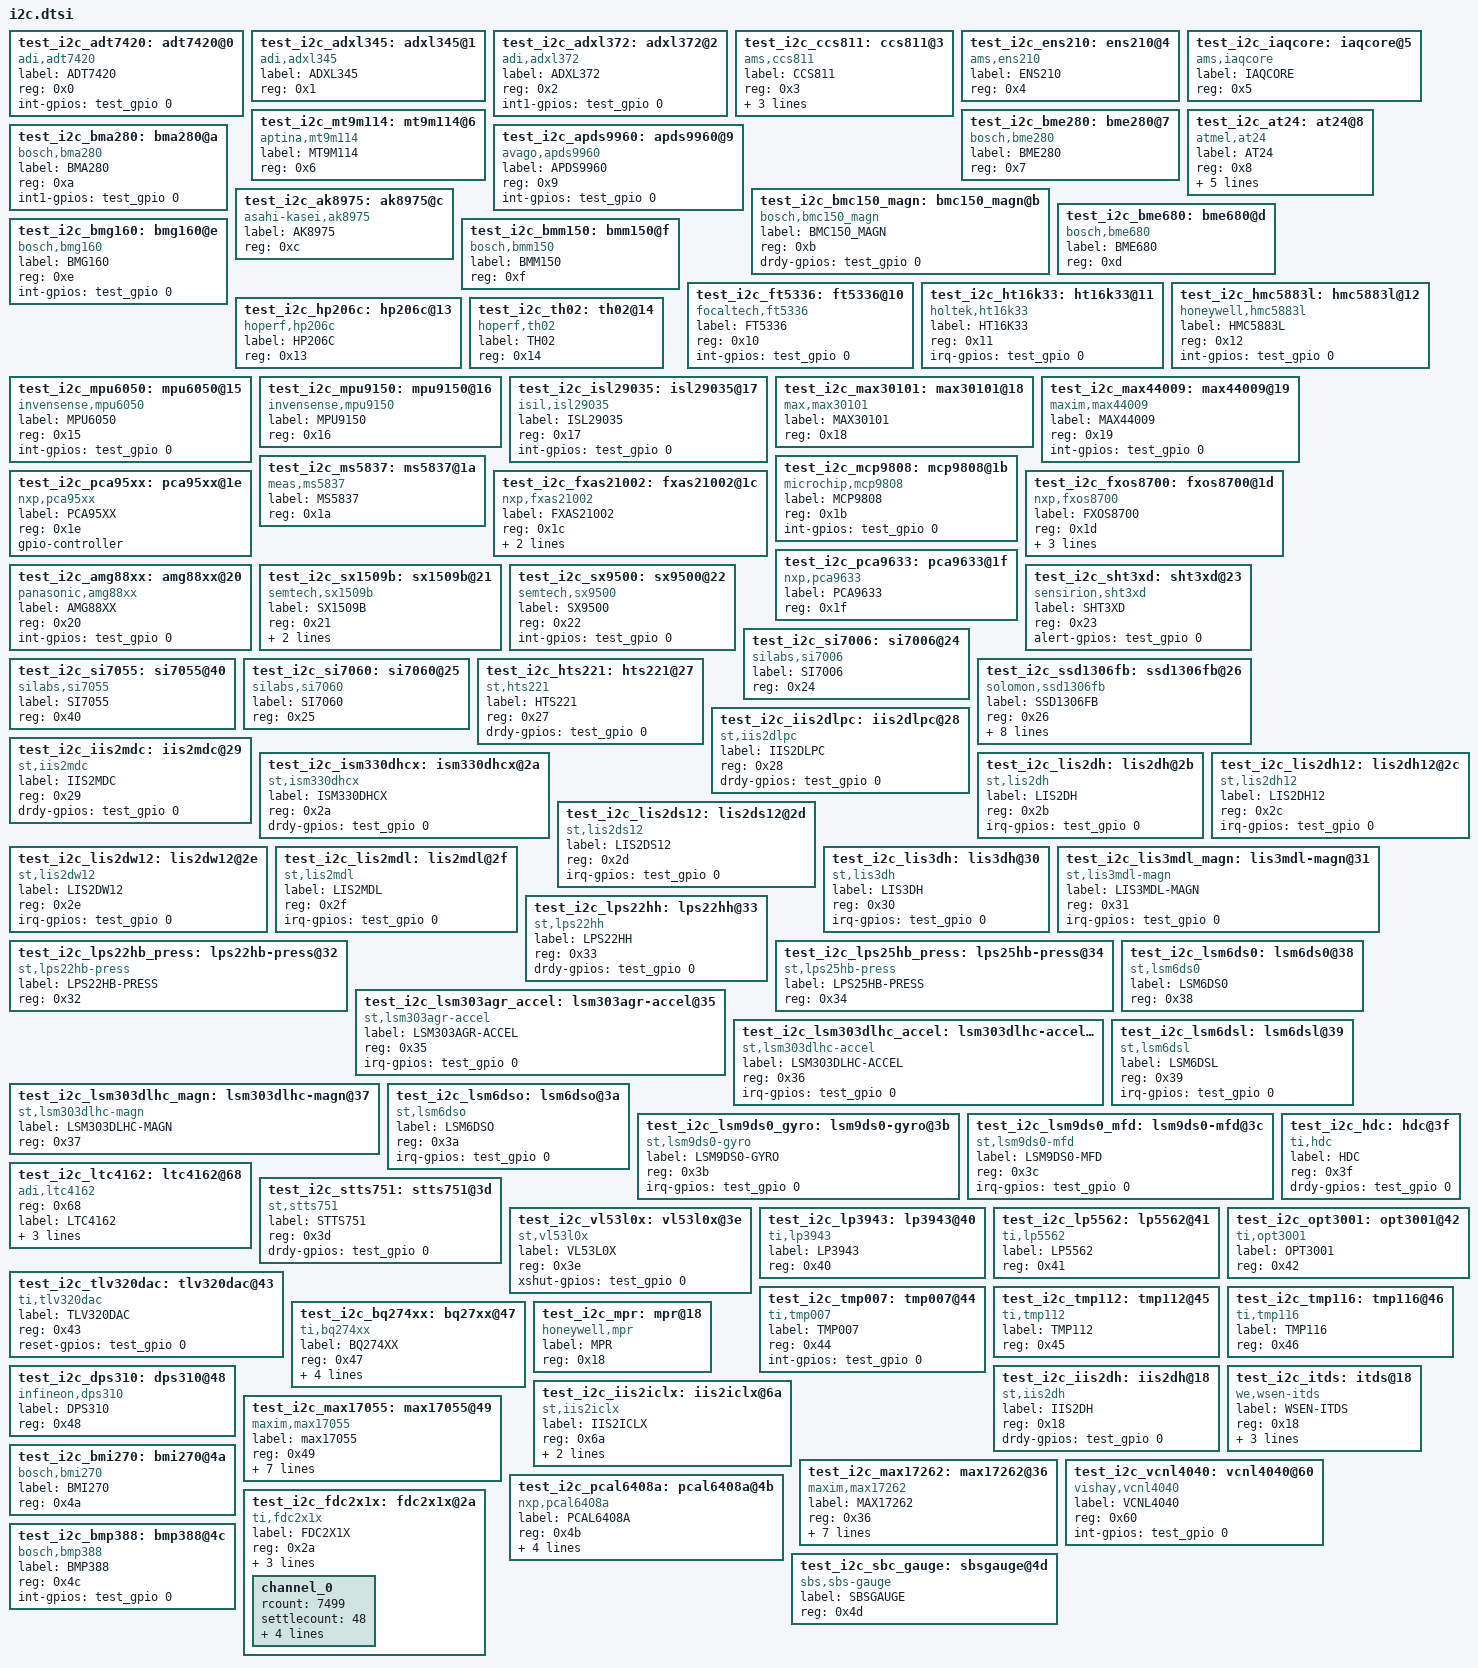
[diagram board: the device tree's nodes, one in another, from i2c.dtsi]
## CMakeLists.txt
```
# SPDX-License-Identifier: Apache-2.0

cmake_minimum_required(VERSION 3.13.1)
find_package(Zephyr REQUIRED HINTS $ENV{ZEPHYR_BASE})
project(build_all)

FILE(GLOB app_sources src/*.c)
target_sources(app PRIVATE ${app_sources})
```

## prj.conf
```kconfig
CONFIG_TEST=y
CONFIG_TEST_USERSPACE=y
CONFIG_SYS_TIMEOUT_LEGACY_API=y
CONFIG_SYS_TIMEOUT_LEGACY_API=y
CONFIG_SYS_TIMEOUT_LEGACY_API=y
CONFIG_SYS_TIMEOUT_LEGACY_API=y
CONFIG_SYS_TIMEOUT_LEGACY_API=y
```

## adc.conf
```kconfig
CONFIG_ADC=y
CONFIG_SPI=y
CONFIG_ADC_MCP320X=y
CONFIG_TEST_USERSPACE=y
```

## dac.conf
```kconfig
CONFIG_DAC=y
CONFIG_SPI=y
CONFIG_DAC_DACX0508=y
CONFIG_TEST_USERSPACE=y
```

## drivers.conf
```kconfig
CONFIG_TEST=y
CONFIG_ADC=y
CONFIG_CAN=y
CONFIG_COUNTER=y
CONFIG_DMA=y
CONFIG_GPIO=y
CONFIG_I2C=y
CONFIG_PINMUX=y
CONFIG_PWM=y
CONFIG_SERIAL=y
CONFIG_SPI=y
CONFIG_WATCHDOG=y
CONFIG_TEST_USERSPACE=y
```

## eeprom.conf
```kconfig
CONFIG_EEPROM=y
CONFIG_GPIO=y
CONFIG_I2C=y
CONFIG_SPI=y
CONFIG_EEPROM_AT24=y
CONFIG_EEPROM_AT25=y
CONFIG_TEST_USERSPACE=y
```

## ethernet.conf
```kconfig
CONFIG_TEST=y
CONFIG_NET_TEST=y
CONFIG_NETWORKING=y
CONFIG_NET_L2_ETHERNET=y
CONFIG_ENTROPY_GENERATOR=y
CONFIG_TEST_RANDOM_GENERATOR=y
CONFIG_TEST_USERSPACE=y

# No board will enable the generic SPI hosted enc28j60 driver by
# default, force it on:
CONFIG_SPI=y
CONFIG_ETH_ENC28J60=y
CONFIG_ETH_ENC28J60_0=y
CONFIG_SYS_TIMEOUT_LEGACY_API=y
CONFIG_SYS_TIMEOUT_LEGACY_API=y
CONFIG_SYS_TIMEOUT_LEGACY_API=y
CONFIG_SYS_TIMEOUT_LEGACY_API=y
CONFIG_SYS_TIMEOUT_LEGACY_API=y
```

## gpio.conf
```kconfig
CONFIG_TEST=y
CONFIG_GPIO=y
CONFIG_TEST_USERSPACE=y
CONFIG_I2C=y
CONFIG_GPIO_SX1509B=y
CONFIG_SPI=y
CONFIG_GPIO_MCP23X17=y
```

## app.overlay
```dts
/*
 * Copyright (c) 2020, Linaro Ltd.
 *
 * SPDX-License-Identifier: Apache-2.0
 *
 * Application overlay for testing driver builds
 *
 * Names in this file should be chosen in a way that won't conflict
 * with real-world devicetree nodes, to allow these tests to run on
 * (and be extended to test) real hardware.
 */

/ {
	test {
		#address-cells = <1>;
		#size-cells = <1>;

		test_gpio: gpio@deadbeef {
			compatible = "vnd,gpio";
			gpio-controller;
			reg = <0xdeadbeef 0x1000>;
			#gpio-cells = <0x2>;
			label = "TEST_GPIO_1";
			status = "okay";

			#include "gpio.dtsi"
		};

		test_i2c: i2c@11112222 {
			#address-cells = <1>;
			#size-cells = <0>;
			compatible = "vnd,i2c";
			reg = <0x11112222 0x1000>;
			label = "TEST_I2C_CTLR";
			status = "okay";
			clock-frequency = <100000>;

			#include "i2c.dtsi"
		};

		test_spi: spi@33334444 {
			#address-cells = <1>;
			#size-cells = <0>;
			compatible = "vnd,spi";
			reg = <0x33334444 0x1000>;
			label = "TEST_SPI_CTLR";
			status = "okay";
			clock-frequency = <2000000>;

			/* one entry for every devices at spi.dtsi */
			cs-gpios = <&test_gpio 0 0>,	/* 0x00 */
				   <&test_gpio 0 0>,
				   <&test_gpio 0 0>,
				   <&test_gpio 0 0>,
				   <&test_gpio 0 0>,
				   <&test_gpio 0 0>,
				   <&test_gpio 0 0>,
				   <&test_gpio 0 0>,
				   <&test_gpio 0 0>,
				   <&test_gpio 0 0>,
				   <&test_gpio 0 0>,
				   <&test_gpio 0 0>,
				   <&test_gpio 0 0>,
				   <&test_gpio 0 0>,
				   <&test_gpio 0 0>,
				   <&test_gpio 0 0>,
				   <&test_gpio 0 0>,	/* 0x10 */
				   <&test_gpio 0 0>,
				   <&test_gpio 0 0>,
				   <&test_gpio 0 0>,
				   <&test_gpio 0 0>,
				   <&test_gpio 0 0>,
				   <&test_gpio 0 0>,
				   <&test_gpio 0 0>,
				   <&test_gpio 0 0>,
				   <&test_gpio 0 0>,
				   <&test_gpio 0 0>,
				   <&test_gpio 0 0>,
				   <&test_gpio 0 0>,
				   <&test_gpio 0 0>,
				   <&test_gpio 0 0>,
				   <&test_gpio 0 0>,
				   <&test_gpio 0 0>,	/* 0x20 */
				   <&test_gpio 0 0>,
				   <&test_gpio 0 0>,
				   <&test_gpio 0 0>,
				   <&test_gpio 0 0>,
				   <&test_gpio 0 0>,
				   <&test_gpio 0 0>,
				   <&test_gpio 0 0>,
				   <&test_gpio 0 0>,
				   <&test_gpio 0 0>,
				   <&test_gpio 0 0>,
				   <&test_gpio 0 0>,
				   <&test_gpio 0 0>,
				   <&test_gpio 0 0>,
				   <&test_gpio 0 0>,
				   <&test_gpio 0 0>,
				   <&test_gpio 0 0>,	/* 0x30 */
				   <&test_gpio 0 0>,
				   <&test_gpio 0 0>,
				   <&test_gpio 0 0>,
				   <&test_gpio 0 0>,
				   <&test_gpio 0 0>,
				   <&test_gpio 0 0>,
				   <&test_gpio 0 0>,
				   <&test_gpio 0 0>,
				   <&test_gpio 0 0>,
				   <&test_gpio 0 0>,
				   <&test_gpio 0 0>,
				   <&test_gpio 0 0>,
				   <&test_gpio 0 0>,
				   <&test_gpio 0 0>,
				   <&test_gpio 0 0>,
				   <&test_gpio 0 0>;	/* 0x40 */

			#include "spi.dtsi"
		};

		test_uart: uart@55556666 {
			compatible = "vnd,serial";
			reg = <0x55556666 0x1000>;
			label = "TEST_UART_CTLR";
			status = "okay";

			#include "uart.dtsi"
		};

		#include "led.dtsi"

		dht22 {
			compatible = "aosong,dht";
			status = "okay";
			label = "DHT22";
			dio-gpios = <&test_gpio 0 0>;
			/* dht22; */
		};
	};
};

/* Put device specific modifications to properties or disabling of devices
 * here to keep the bus specific dtsi files (i2c.dtsi, spi.dtsi, etc..)
 * pristine
 */

/* setup valid params for the device */
&test_i2c_at24 {
	reg = <0x8>;
	size = <32768>;
	pagesize = <64>;
	address-width = <16>;
	timeout = <5>;
};

/* disable device to conflict with i2c version */
&test_i2c_iis2dlpc {
	status = "disabled";
};

/* disable device to conflict with i2c version */
&test_i2c_ism330dhcx {
	status = "disabled";
};

/* disable device to conflict with i2c version */
&test_i2c_lis2dh {
	status = "disabled";
};

/* disable device to conflict with i2c version */
&test_i2c_lis2ds12 {
	status = "disabled";
};

/* disable device to conflict with i2c version */
&test_i2c_lis2dw12 {
	status = "disabled";
};

/* disable device to conflict with i2c version */
&test_i2c_lis2mdl {
	status = "disabled";
};

/* disable device to conflict with i2c version */
&test_i2c_lps22hh {
	status = "disabled";
};

/* disable device to conflict with i2c version */
&test_i2c_lsm6dsl {
	status = "disabled";
};

/* disable device to conflict with i2c version */
&test_i2c_lsm6dso {
	status = "disabled";
};

/* setup valid params for the device */
&test_spi_at25 {
	size = <32768>;
	pagesize = <64>;
	address-width = <16>;
	timeout = <5>;
};

/* disable device to conflict with i2c version */
&test_spi_bme280 {
	status = "disabled";
};

/* setup valid params for the device */
&test_spi_enc28j60 {
	local-mac-address = [00 00 00 00 00 00];
};

/* disable device to conflict with i2c version */
&test_spi_iis2iclx {
	status = "disabled";
};

/* disable device to conflict with i2c version */
&test_spi_iis2mdc {
	status = "disabled";
};

/* setup valid params for the device */
&test_spi_iis3dhhc {
	irq-gpios = <&test_gpio 0 0>, <&test_gpio 0 0>;
};

/* disable device to conflict with i2c version */
&test_spi_iis2dh {
	status = "disabled";
};
```

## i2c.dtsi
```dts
/*
 * Copyright (c) 2020, Linaro Ltd.
 *
 * SPDX-License-Identifier: Apache-2.0
 *
 * Application overlay for i2c devices
 */

test_i2c_adt7420: adt7420@0 {
	compatible = "adi,adt7420";
	label = "ADT7420";
	reg = <0x0>;
	int-gpios = <&test_gpio 0 0>;
};

test_i2c_adxl345: adxl345@1 {
	compatible = "adi,adxl345";
	label = "ADXL345";
	reg = <0x1>;
};

test_i2c_adxl372: adxl372@2 {
	compatible = "adi,adxl372";
	label = "ADXL372";
	reg = <0x2>;
	int1-gpios = <&test_gpio 0 0>;
};

test_i2c_ccs811: ccs811@3 {
	compatible = "ams,ccs811";
	label = "CCS811";
	reg = <0x3>;
	wake-gpios = <&test_gpio 0 0>;
	reset-gpios = <&test_gpio 0 0>;
	irq-gpios = <&test_gpio 0 0>;
};

test_i2c_ens210: ens210@4 {
	compatible = "ams,ens210";
	label = "ENS210";
	reg = <0x4>;
};

test_i2c_iaqcore: iaqcore@5 {
	compatible = "ams,iaqcore";
	label = "IAQCORE";
	reg = <0x5>;
};

test_i2c_mt9m114: mt9m114@6 {
	compatible = "aptina,mt9m114";
	label = "MT9M114";
	reg = <0x6>;
};

test_i2c_bme280: bme280@7 {
	compatible = "bosch,bme280";
	label = "BME280";
	reg = <0x7>;
};

test_i2c_at24: at24@8 {
	compatible = "atmel,at24";
	label = "AT24";
	reg = <0x8>;
	size = <0>;
	pagesize = <0>;
	address-width = <0>;
	timeout = <0>;
	wp-gpios = <&test_gpio 0 0>;
	/* read-only; */
};

test_i2c_apds9960: apds9960@9 {
	compatible = "avago,apds9960";
	label = "APDS9960";
	reg = <0x9>;
	int-gpios = <&test_gpio 0 0>;
};

test_i2c_bma280: bma280@a {
	compatible = "bosch,bma280";
	label = "BMA280";
	reg = <0xa>;
	int1-gpios = <&test_gpio 0 0>;
	/* is-bmc150; */
};

test_i2c_bmc150_magn: bmc150_magn@b {
	compatible = "bosch,bmc150_magn";
	label = "BMC150_MAGN";
	reg = <0xb>;
	drdy-gpios = <&test_gpio 0 0>;
};

test_i2c_ak8975: ak8975@c {
	compatible = "asahi-kasei,ak8975";
	label = "AK8975";
	reg = <0xc>;
};

test_i2c_bme680: bme680@d {
	compatible = "bosch,bme680";
	label = "BME680";
	reg = <0xd>;
};

test_i2c_bmg160: bmg160@e {
	compatible = "bosch,bmg160";
	label = "BMG160";
	reg = <0xe>;
	int-gpios = <&test_gpio 0 0>;
};

test_i2c_bmm150: bmm150@f {
	compatible = "bosch,bmm150";
	label = "BMM150";
	reg = <0xf>;
};

test_i2c_ft5336: ft5336@10 {
	compatible = "focaltech,ft5336";
	label = "FT5336";
	reg = <0x10>;
	int-gpios = <&test_gpio 0 0>;
};

test_i2c_ht16k33: ht16k33@11 {
	compatible = "holtek,ht16k33";
	label = "HT16K33";
	reg = <0x11>;
	#address-cells = <1>;
	#size-cells = <0>;
	irq-gpios = <&test_gpio 0 0>;
};

test_i2c_hmc5883l: hmc5883l@12 {
	compatible = "honeywell,hmc5883l";
	label = "HMC5883L";
	reg = <0x12>;
	int-gpios = <&test_gpio 0 0>;
};

test_i2c_hp206c: hp206c@13 {
	compatible = "hoperf,hp206c";
	label = "HP206C";
	reg = <0x13>;
};

test_i2c_th02: th02@14 {
	compatible = "hoperf,th02";
	label = "TH02";
	reg = <0x14>;
};

test_i2c_mpu6050: mpu6050@15 {
	compatible = "invensense,mpu6050";
	label = "MPU6050";
	reg = <0x15>;
	int-gpios = <&test_gpio 0 0>;
};

test_i2c_mpu9150: mpu9150@16 {
	compatible = "invensense,mpu9150";
	label = "MPU9150";
	reg = <0x16>;
};

test_i2c_isl29035: isl29035@17 {
	compatible = "isil,isl29035";
	label = "ISL29035";
	reg = <0x17>;
	int-gpios = <&test_gpio 0 0>;
};

test_i2c_max30101: max30101@18 {
	compatible = "max,max30101";
	label = "MAX30101";
	reg = <0x18>;
};

test_i2c_max44009: max44009@19 {
	compatible = "maxim,max44009";
	label = "MAX44009";
	reg = <0x19>;
	int-gpios = <&test_gpio 0 0>;
};

test_i2c_ms5837: ms5837@1a {
	compatible = "meas,ms5837";
	label = "MS5837";
	reg = <0x1a>;
};

test_i2c_mcp9808: mcp9808@1b {
	compatible = "microchip,mcp9808";
	label = "MCP9808";
	reg = <0x1b>;
	int-gpios = <&test_gpio 0 0>;
};

test_i2c_fxas21002: fxas21002@1c {
	compatible = "nxp,fxas21002";
	label = "FXAS21002";
	reg = <0x1c>;
	int1-gpios = <&test_gpio 0 0>;
	int2-gpios = <&test_gpio 0 0>;
};

test_i2c_fxos8700: fxos8700@1d {
	compatible = "nxp,fxos8700";
	label = "FXOS8700";
	reg = <0x1d>;
	reset-gpios = <&test_gpio 0 0>;
	int1-gpios = <&test_gpio 0 0>;
	int2-gpios = <&test_gpio 0 0>;
};

test_i2c_pca95xx: pca95xx@1e {
	compatible = "nxp,pca95xx";
	label = "PCA95XX";
	reg = <0x1e>;
	/* has-pud; */
	#gpio-cells = <2>;
	gpio-controller;
};

test_i2c_pca9633: pca9633@1f {
	compatible = "nxp,pca9633";
	label = "PCA9633";
	reg = <0x1f>;
};

test_i2c_amg88xx: amg88xx@20 {
	compatible = "panasonic,amg88xx";
	label = "AMG88XX";
	reg = <0x20>;
	int-gpios = <&test_gpio 0 0>;
};

test_i2c_sx1509b: sx1509b@21 {
	compatible = "semtech,sx1509b";
	label = "SX1509B";
	reg = <0x21>;
	#gpio-cells = <2>;
	ngpios = <16>;
	gpio-controller;
};

test_i2c_sx9500: sx9500@22 {
	compatible = "semtech,sx9500";
	label = "SX9500";
	reg = <0x22>;
	int-gpios = <&test_gpio 0 0>;
};

test_i2c_sht3xd: sht3xd@23 {
	compatible = "sensirion,sht3xd";
	label = "SHT3XD";
	reg = <0x23>;
	alert-gpios = <&test_gpio 0 0>;
};

test_i2c_si7006: si7006@24 {
	compatible = "silabs,si7006";
	label = "SI7006";
	reg = <0x24>;
};

test_i2c_si7055: si7055@40 {
	compatible = "silabs,si7055";
	label = "SI7055";
	reg = <0x40>;
};

test_i2c_si7060: si7060@25 {
	compatible = "silabs,si7060";
	label = "SI7060";
	reg = <0x25>;
};

test_i2c_ssd1306fb: ssd1306fb@26 {
	compatible = "solomon,ssd1306fb";
	label = "SSD1306FB";
	reg = <0x26>;
	height = <0>;
	width = <0>;
	segment-offset = <0>;
	page-offset = <0>;
	display-offset = <0>;
	multiplex-ratio = <0>;
	/* segment-remap; */
	/* com-invdir; */
	/* com-sequential; */
	prechargep = <0>;
	reset-gpios = <&test_gpio 0 0>;
};

test_i2c_hts221: hts221@27 {
	compatible = "st,hts221";
	label = "HTS221";
	reg = <0x27>;
	drdy-gpios = <&test_gpio 0 0>;
};

test_i2c_iis2dlpc: iis2dlpc@28 {
	compatible = "st,iis2dlpc";
	label = "IIS2DLPC";
	reg = <0x28>;
	drdy-gpios = <&test_gpio 0 0>;
};

test_i2c_iis2mdc: iis2mdc@29 {
	compatible = "st,iis2mdc";
	label = "IIS2MDC";
	reg = <0x29>;
	drdy-gpios = <&test_gpio 0 0>;
};

test_i2c_ism330dhcx: ism330dhcx@2a {
	compatible = "st,ism330dhcx";
	label = "ISM330DHCX";
	reg = <0x2a>;
	drdy-gpios = <&test_gpio 0 0>;
};

test_i2c_lis2dh: lis2dh@2b {
	compatible = "st,lis2dh";
	label = "LIS2DH";
	reg = <0x2b>;
	irq-gpios = <&test_gpio 0 0>;
	/* disconnect-sdo-sa0-pull-up; */
};

test_i2c_lis2dh12: lis2dh12@2c {
	compatible = "st,lis2dh12";
	label = "LIS2DH12";
	reg = <0x2c>;
	irq-gpios = <&test_gpio 0 0>;
};

test_i2c_lis2ds12: lis2ds12@2d {
	compatible = "st,lis2ds12";
	label = "LIS2DS12";
	reg = <0x2d>;
	irq-gpios = <&test_gpio 0 0>;
};

test_i2c_lis2dw12: lis2dw12@2e {
	compatible = "st,lis2dw12";
	label = "LIS2DW12";
	reg = <0x2e>;
	irq-gpios = <&test_gpio 0 0>;
};

test_i2c_lis2mdl: lis2mdl@2f {
	compatible = "st,lis2mdl";
	label = "LIS2MDL";
	reg = <0x2f>;
	irq-gpios = <&test_gpio 0 0>;
};

test_i2c_lis3dh: lis3dh@30 {
	compatible = "st,lis3dh";
	label = "LIS3DH";
	reg = <0x30>;
	irq-gpios = <&test_gpio 0 0>;
};

test_i2c_lis3mdl_magn: lis3mdl-magn@31 {
	compatible = "st,lis3mdl-magn";
	label = "LIS3MDL-MAGN";
	reg = <0x31>;
	irq-gpios = <&test_gpio 0 0>;
};

test_i2c_lps22hb_press: lps22hb-press@32 {
	compatible = "st,lps22hb-press";
	label = "LPS22HB-PRESS";
	reg = <0x32>;
};

test_i2c_lps22hh: lps22hh@33 {
	compatible = "st,lps22hh";
	label = "LPS22HH";
	reg = <0x33>;
	drdy-gpios = <&test_gpio 0 0>;
};

test_i2c_lps25hb_press: lps25hb-press@34 {
	compatible = "st,lps25hb-press";
	label = "LPS25HB-PRESS";
	reg = <0x34>;
};

test_i2c_lsm303agr_accel: lsm303agr-accel@35 {
	compatible = "st,lsm303agr-accel";
	label = "LSM303AGR-ACCEL";
	reg = <0x35>;
	irq-gpios = <&test_gpio 0 0>;
	/* disconnect-sdo-sa0-pull-up; */
};

test_i2c_lsm303dlhc_accel: lsm303dlhc-accel@36 {
	compatible = "st,lsm303dlhc-accel";
	label = "LSM303DLHC-ACCEL";
	reg = <0x36>;
	irq-gpios = <&test_gpio 0 0>;
	/* disconnect-sdo-sa0-pull-up; */
};

test_i2c_lsm303dlhc_magn: lsm303dlhc-magn@37 {
	compatible = "st,lsm303dlhc-magn";
	label = "LSM303DLHC-MAGN";
	reg = <0x37>;
};

test_i2c_lsm6ds0: lsm6ds0@38 {
	compatible = "st,lsm6ds0";
	label = "LSM6DS0";
	reg = <0x38>;
};

test_i2c_lsm6dsl: lsm6dsl@39 {
	compatible = "st,lsm6dsl";
	label = "LSM6DSL";
	reg = <0x39>;
	irq-gpios = <&test_gpio 0 0>;
};

test_i2c_lsm6dso: lsm6dso@3a {
	compatible = "st,lsm6dso";
	label = "LSM6DSO";
	reg = <0x3a>;
	irq-gpios = <&test_gpio 0 0>;
};

test_i2c_lsm9ds0_gyro: lsm9ds0-gyro@3b {
	compatible = "st,lsm9ds0-gyro";
	label = "LSM9DS0-GYRO";
	reg = <0x3b>;
	irq-gpios = <&test_gpio 0 0>;
};

test_i2c_lsm9ds0_mfd: lsm9ds0-mfd@3c {
	compatible = "st,lsm9ds0-mfd";
	label = "LSM9DS0-MFD";
	reg = <0x3c>;
	irq-gpios = <&test_gpio 0 0>;
};

test_i2c_ltc4162: ltc4162@68 {
	compatible = "adi,ltc4162";
	reg = <0x68>;
	label = "LTC4162";
	rsnsb-micro-ohms = <10>;
	rsnsi-micro-ohms = <10>;
	cell-count = <2>;
};

test_i2c_stts751: stts751@3d {
	compatible = "st,stts751";
	label = "STTS751";
	reg = <0x3d>;
	drdy-gpios = <&test_gpio 0 0>;
};

test_i2c_vl53l0x: vl53l0x@3e {
	compatible = "st,vl53l0x";
	label = "VL53L0X";
	reg = <0x3e>;
	xshut-gpios = <&test_gpio 0 0>;
};

test_i2c_hdc: hdc@3f {
	compatible = "ti,hdc";
	label = "HDC";
	reg = <0x3f>;
	drdy-gpios = <&test_gpio 0 0>;
};

test_i2c_lp3943: lp3943@40 {
	compatible = "ti,lp3943";
	label = "LP3943";
	reg = <0x40>;
};

test_i2c_lp5562: lp5562@41 {
	compatible = "ti,lp5562";
	label = "LP5562";
	reg = <0x41>;
};

test_i2c_opt3001: opt3001@42 {
	compatible = "ti,opt3001";
	label = "OPT3001";
	reg = <0x42>;
};

test_i2c_tlv320dac: tlv320dac@43 {
	compatible = "ti,tlv320dac";
	label = "TLV320DAC";
	reg = <0x43>;
	reset-gpios = <&test_gpio 0 0>;
};

test_i2c_tmp007: tmp007@44 {
	compatible = "ti,tmp007";
	label = "TMP007";
	reg = <0x44>;
	int-gpios = <&test_gpio 0 0>;
};

test_i2c_tmp112: tmp112@45 {
	compatible = "ti,tmp112";
	label = "TMP112";
	reg = <0x45>;
};

test_i2c_tmp116: tmp116@46 {
	compatible = "ti,tmp116";
	label = "TMP116";
	reg = <0x46>;
};

test_i2c_bq274xx: bq27xx@47 {
	compatible = "ti,bq274xx";
	label = "BQ274XX";
	reg = <0x47>;
	design-voltage = <3700>;
	design-capacity = <1800>;
	taper-current = <45>;
	terminate-voltage = <3000>;
};

test_i2c_mpr: mpr@18 {
	compatible = "honeywell,mpr";
	label = "MPR";
	reg = <0x18>;
};

test_i2c_dps310: dps310@48 {
		compatible = "infineon,dps310";
		label = "DPS310";
		reg = <0x48>;
};

test_i2c_iis2dh: iis2dh@18 {
	compatible = "st,iis2dh";
	label = "IIS2DH";
	reg = <0x18>;
	drdy-gpios = <&test_gpio 0 0>;
};

test_i2c_iis2iclx: iis2iclx@6a {
	compatible = "st,iis2iclx";
	label = "IIS2ICLX";
	reg = <0x6a>;
	drdy-gpios = <&test_gpio 0 0>;
	int-pin = <1>;
};

test_i2c_itds: itds@18 {
	compatible = "we,wsen-itds";
	label = "WSEN-ITDS";
	reg = <0x18>;
	int-gpios = <&test_gpio 0 0>;
	odr = "800";
	op-mode = "high-perf";
};

test_i2c_max17055: max17055@49 {
	compatible = "maxim,max17055";
	label = "max17055";
	reg = <0x49>;
	design-capacity = <1500>;
	design-voltage = <3860>;
	desired-charging-current = <2000>;
	desired-voltage = <4400>;
	i-chg-term = <100>;
	rsense-mohms = <5>;
	v-empty = <3300>;
};

test_i2c_max17262: max17262@36 {
	compatible = "maxim,max17262";
	label = "MAX17262";
	reg = <0x36>;
	design-voltage = <3600>;
	desired-voltage = <3600>;
	desired-charging-current = <2000>;
	design-cap = <17000>;
	empty-voltage = <3300>;
	recovery-voltage = <3880>;
	charge-voltage = <3600>;
};

test_i2c_vcnl4040: vcnl4040@60 {
	compatible = "vishay,vcnl4040";
	label = "VCNL4040";
	reg = <0x60>;
	int-gpios = <&test_gpio 0 0>;
};

test_i2c_bmi270: bmi270@4a {
	compatible = "bosch,bmi270";
	label = "BMI270";
	reg = <0x4a>;
};

test_i2c_pcal6408a: pcal6408a@4b {
	compatible = "nxp,pcal6408a";
	label = "PCAL6408A";
	reg = <0x4b>;
	gpio-controller;
	#gpio-cells = <2>;
	ngpios = <8>;
	int-gpios = <&test_gpio 0 0>;
	reset-gpios = <&test_gpio 0 0>;
};

test_i2c_fdc2x1x: fdc2x1x@2a {
	compatible = "ti,fdc2x1x";
	label = "FDC2X1X";
	reg = <0x2a>;
	intb-gpios = <&test_gpio 0 0>;
	deglitch = <5>;
	fref = <43360>;
	channel_0 {
		rcount = <7499>;
		settlecount = <48>;
		fref-divider = <1>;
		idrive = <10>;
		fin-sel = <2>;
		inductance = <18>;
	};
};

test_i2c_bmp388: bmp388@4c {
	compatible = "bosch,bmp388";
	label = "BMP388";
	reg = <0x4c>;
	int-gpios = <&test_gpio 0 0>;
};

test_i2c_sbc_gauge: sbsgauge@4d {
	compatible = "sbs,sbs-gauge";
	label = "SBSGAUGE";
	reg = <0x4d>;
};
```

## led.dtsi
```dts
/*
 * Copyright (c) 2021, Nordic Semiconductor ASA
 *
 * SPDX-License-Identifier: Apache-2.0
 *
 * Application overlay for led devices
 */

test_gpio_leds {
	compatible = "gpio-leds";
	test_gpio_led0: test_gpio_led_0 {
		gpios = <&test_gpio 0 0>;
		label = "Test GPIO LED";
	};
};
```

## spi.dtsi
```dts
/*
 * Copyright (c) 2020, Linaro Ltd.
 *
 * SPDX-License-Identifier: Apache-2.0
 *
 * Application overlay for spi devices
 */

test_spi_adxl362: adxl362@0 {
	compatible = "adi,adxl362";
	label = "ADXL362";
	reg = <0x0>;
	spi-max-frequency = <0>;
	int1-gpios = <&test_gpio 0 0>;
};

test_spi_adxl372: adxl372@1 {
	compatible = "adi,adxl372";
	label = "ADXL372";
	reg = <0x1>;
	spi-max-frequency = <0>;
	int1-gpios = <&test_gpio 0 0>;
};

test_spi_apa102: apa102@2 {
	compatible = "apa,apa102";
	label = "APA102";
	reg = <0x2>;
	spi-max-frequency = <0>;
};

test_spi_at25: at25@3 {
	compatible = "atmel,at25";
	label = "AT25";
	reg = <0x3>;
	spi-max-frequency = <0>;
	size = <0>;
	pagesize = <0>;
	address-width = <0>;
	timeout = <0>;
	wp-gpios = <&test_gpio 0 0>;
	/* read-only; */
};

test_spi_rf2xx: rf2xx@4 {
	compatible = "atmel,rf2xx";
	label = "RF2XX";
	reg = <0x4>;
	spi-max-frequency = <0>;
	irq-gpios = <&test_gpio 0 0>;
	reset-gpios = <&test_gpio 0 0>;
	slptr-gpios = <&test_gpio 0 0>;
	dig2-gpios = <&test_gpio 0 0>;
	clkm-gpios = <&test_gpio 0 0>;
};

test_spi_winc1500: winc1500@5 {
	compatible = "atmel,winc1500";
	label = "WINC1500";
	reg = <0x5>;
	spi-max-frequency = <0>;
	irq-gpios = <&test_gpio 0 0>;
	reset-gpios = <&test_gpio 0 0>;
	enable-gpios = <&test_gpio 0 0>;
};

test_spi_bme280: bme280@6 {
	compatible = "bosch,bme280";
	label = "BME280";
	reg = <0x6>;
	spi-max-frequency = <0>;
};

test_spi_bmi160: bmi160@7 {
	compatible = "bosch,bmi160";
	label = "BMI160";
	reg = <0x7>;
	spi-max-frequency = <0>;
	int-gpios = <&test_gpio 0 0>;
};

test_spi_lpd8803: lpd8803@8 {
	compatible = "colorway,lpd8803";
	label = "LPD8803";
	reg = <0x8>;
	spi-max-frequency = <0>;
};

test_spi_lpd8806: lpd8806@9 {
	compatible = "colorway,lpd8806";
	label = "LPD8806";
	reg = <0x9>;
	spi-max-frequency = <0>;
};

test_spi_gd7965: gd7965@a {
	compatible = "gooddisplay,gd7965";
	label = "GD7965";
	reg = <0xa>;
	spi-max-frequency = <0>;
	height = <0>;
	width = <0>;
	reset-gpios = <&test_gpio 0 0>;
	dc-gpios = <&test_gpio 0 0>;
	busy-gpios = <&test_gpio 0 0>;
	pwr = [];
	softstart = [];
	cdi = <0>;
	tcon = <0>;
};

test_spi_ili9340: ili9340@b {
	compatible = "ilitek,ili9340";
	label = "ILI9340";
	reg = <0xb>;
	spi-max-frequency = <0>;
	reset-gpios = <&test_gpio 0 0>;
	cmd-data-gpios = <&test_gpio 0 0>;
};

test_spi_eswifi: eswifi@c {
	compatible = "inventek,eswifi";
	label = "ESWIFI";
	reg = <0xc>;
	spi-max-frequency = <0>;
	resetn-gpios = <&test_gpio 0 0>;
	data-gpios = <&test_gpio 0 0>;
	wakeup-gpios = <&test_gpio 0 0>;
	boot0-gpios = <&test_gpio 0 0>;
};

test_spi_spi_nor: spi-nor@d {
	compatible = "jedec,spi-nor";
	label = "SPI-NOR";
	reg = <0xd>;
	spi-max-frequency = <0>;
	wp-gpios = <&test_gpio 0 0>;
	hold-gpios = <&test_gpio 0 0>;
	reset-gpios = <&test_gpio 0 0>;
	jedec-id = [];
	/* requires-ulbpr; */
	/* has-dpd; */
	size = <0>;
};

test_spi_ms5607: ms5607@e {
	compatible = "meas,ms5607";
	label = "MS5607";
	reg = <0xe>;
	spi-max-frequency = <0>;
};

test_spi_enc28j60: enc28j60@f {
	compatible = "microchip,enc28j60";
	label = "ENC28J60";
	reg = <0xf>;
	spi-max-frequency = <0>;
	int-gpios = <&test_gpio 0 0>;
};

test_spi_enc424j600: enc424j600@10 {
	compatible = "microchip,enc424j600";
	label = "ENC424J600";
	reg = <0x10>;
	spi-max-frequency = <0>;
	int-gpios = <&test_gpio 0 0>;
};
test_spi_mcp23s17: mcp23s17@11 {
	compatible = "microchip,mcp23s17";
	label = "GPIO_E0";
	spi-max-frequency = <0>;
	reg = <0x11>;
	gpio-controller;
	#gpio-cells = <2>;
	ngpios = <16>;
};

test_spi_mcp2515: mcp2515@12 {
	compatible = "microchip,mcp2515";
	label = "MCP2515";
	reg = <0x12>;
	spi-max-frequency = <0>;
	osc-freq = <0>;
	int-gpios = <&test_gpio 0 0>;
	#address-cells = <1>;
	#size-cells = <0>;
	bus-speed = <0>;
	sjw = <0>;
	prop-seg = <0>;
	phase-seg1 = <0>;
	phase-seg2 = <0>;
};

test_spi_mcr20a: mcr20a@13 {
	compatible = "nxp,mcr20a";
	label = "MCR20A";
	reg = <0x13>;
	spi-max-frequency = <0>;
	irqb-gpios = <&test_gpio 0 0>;
	reset-gpios = <&test_gpio 0 0>;
};

test_spi_sx1276: sx1276@14 {
	compatible = "semtech,sx1276";
	label = "SX1276";
	reg = <0x14>;
	spi-max-frequency = <0>;
	reset-gpios = <&test_gpio 0 0>;
	dio-gpios = <&test_gpio 0 0>;
	power-amplifier-output = "rfo";
};

test_spi_st7789v: st7789v@15 {
	compatible = "sitronix,st7789v";
	label = "ST7789V";
	reg = <0x15>;
	spi-max-frequency = <0>;
	reset-gpios = <&test_gpio 0 0>;
	cmd-data-gpios = <&test_gpio 0 0>;
	height = <0>;
	width = <0>;
	x-offset = <0>;
	y-offset = <0>;
	vcom = <0>;
	gctrl = <0>;
	mdac = <0>;
	lcm = <0>;
	colmod = <0>;
	gamma = <0>;
	porch-param = [];
	cmd2en-param = [];
	pwctrl1-param = [];
	pvgam-param = [];
	nvgam-param = [];
	ram-param = [];
	rgb-param = [];
};

test_spi_ssd16xxfb: ssd16xxfb@16 {
	compatible = "solomon,ssd16xxfb";
	label = "SSD16XXFB";
	reg = <0x16>;
	spi-max-frequency = <0>;
	height = <0>;
	width = <0>;
	pp-height-bits = <0>;
	pp-width-bits = <0>;
	gdv = [];
	sdv = [];
	vcom = <0>;
	border-waveform = <0>;
	/* orientation-flipped; */
	reset-gpios = <&test_gpio 0 0>;
	dc-gpios = <&test_gpio 0 0>;
	busy-gpios = <&test_gpio 0 0>;
	lut-initial = [];
	lut-default = [];
};

test_spi_iis2dlpc: iis2dlpc@17 {
	compatible = "st,iis2dlpc";
	label = "IIS2DLPC";
	reg = <0x17>;
	spi-max-frequency = <0>;
	drdy-gpios = <&test_gpio 0 0>;
};

test_spi_iis2mdc: iis2mdc@18 {
	compatible = "st,iis2mdc";
	label = "IIS2MDC";
	reg = <0x18>;
	spi-max-frequency = <0>;
	drdy-gpios = <&test_gpio 0 0>;
};

test_spi_iis3dhhc: iis3dhhc@19 {
	compatible = "st,iis3dhhc";
	label = "IIS3DHHC";
	reg = <0x19>;
	spi-max-frequency = <0>;
	irq-gpios = <&test_gpio 0 0>;
};

test_spi_ism330dhcx: ism330dhcx@1a {
	compatible = "st,ism330dhcx";
	label = "ISM330DHCX";
	reg = <0x1a>;
	spi-max-frequency = <0>;
	drdy-gpios = <&test_gpio 0 0>;
};

test_spi_lis2dh: lis2dh@1b {
	compatible = "st,lis2dh";
	label = "LIS2DH";
	reg = <0x1b>;
	spi-max-frequency = <0>;
	irq-gpios = <&test_gpio 0 0>;
	/* disconnect-sdo-sa0-pull-up; */
};

test_spi_lis2ds12: lis2ds12@1c {
	compatible = "st,lis2ds12";
	label = "LIS2DS12";
	reg = <0x1c>;
	spi-max-frequency = <0>;
	irq-gpios = <&test_gpio 0 0>;
};

test_spi_lis2dw12: lis2dw12@1d {
	compatible = "st,lis2dw12";
	label = "LIS2DW12";
	reg = <0x1d>;
	spi-max-frequency = <0>;
	irq-gpios = <&test_gpio 0 0>;
};

test_spi_lis2mdl: lis2mdl@1e {
	compatible = "st,lis2mdl";
	label = "LIS2MDL";
	reg = <0x1e>;
	spi-max-frequency = <0>;
	irq-gpios = <&test_gpio 0 0>;
};

test_spi_lps22hh: lps22hh@1f {
	compatible = "st,lps22hh";
	label = "LPS22HH";
	reg = <0x1f>;
	spi-max-frequency = <0>;
	drdy-gpios = <&test_gpio 0 0>;
};

test_spi_lsm303agr_accel: lsm303agr-accel@20 {
	compatible = "st,lsm303agr-accel";
	label = "LSM303AGR-ACCEL";
	reg = <0x20>;
	spi-max-frequency = <0>;
	irq-gpios = <&test_gpio 0 0>;
	/* disconnect-sdo-sa0-pull-up; */
};

test_spi_lsm6dsl: lsm6dsl@21 {
	compatible = "st,lsm6dsl";
	label = "LSM6DSL";
	reg = <0x21>;
	spi-max-frequency = <0>;
	irq-gpios = <&test_gpio 0 0>;
};

test_spi_lsm6dso: lsm6dso@22 {
	compatible = "st,lsm6dso";
	label = "LSM6DSO";
	reg = <0x22>;
	spi-max-frequency = <0>;
	irq-gpios = <&test_gpio 0 0>;
};

test_spi_cc1200: cc1200@23 {
	compatible = "ti,cc1200";
	label = "CC1200";
	reg = <0x23>;
	spi-max-frequency = <0>;
	int-gpios = <&test_gpio 0 0>;
};

test_spi_cc2520: cc2520@24 {
	compatible = "ti,cc2520";
	label = "CC2520";
	reg = <0x24>;
	spi-max-frequency = <0>;
	vreg-en-gpios = <&test_gpio 0 0>;
	reset-gpios = <&test_gpio 0 0>;
	fifo-gpios = <&test_gpio 0 0>;
	cca-gpios = <&test_gpio 0 0>;
	sfd-gpios = <&test_gpio 0 0>;
	fifop-gpios = <&test_gpio 0 0>;
};

test_spi_lmp90077: lmp90077@25 {
	compatible = "ti,lmp90077";
	label = "LMP90077";
	reg = <0x25>;
	spi-max-frequency = <0>;
	drdyb-gpios = <&test_gpio 0 0>;
	#io-channel-cells = <2>;
};

test_spi_lmp90078: lmp90078@26 {
	compatible = "ti,lmp90078";
	label = "LMP90078";
	reg = <0x26>;
	spi-max-frequency = <0>;
	drdyb-gpios = <&test_gpio 0 0>;
	#io-channel-cells = <2>;
};

test_spi_lmp90079: lmp90079@27 {
	compatible = "ti,lmp90079";
	label = "LMP90079";
	reg = <0x27>;
	spi-max-frequency = <0>;
	drdyb-gpios = <&test_gpio 0 0>;
	#io-channel-cells = <2>;
};

test_spi_lmp90080: lmp90080@28 {
	compatible = "ti,lmp90080";
	label = "LMP90080";
	reg = <0x28>;
	spi-max-frequency = <0>;
	drdyb-gpios = <&test_gpio 0 0>;
	#io-channel-cells = <2>;
};

test_spi_lmp90097: lmp90097@29 {
	compatible = "ti,lmp90097";
	label = "LMP90097";
	reg = <0x29>;
	spi-max-frequency = <0>;
	drdyb-gpios = <&test_gpio 0 0>;
	#io-channel-cells = <2>;
};

test_spi_lmp90098: lmp90098@2a {
	compatible = "ti,lmp90098";
	label = "LMP90098";
	reg = <0x2a>;
	spi-max-frequency = <0>;
	drdyb-gpios = <&test_gpio 0 0>;
	#io-channel-cells = <2>;
};

test_spi_lmp90099: lmp90099@2b {
	compatible = "ti,lmp90099";
	label = "LMP90099";
	reg = <0x2b>;
	spi-max-frequency = <0>;
	drdyb-gpios = <&test_gpio 0 0>;
	#io-channel-cells = <2>;
};

test_spi_lmp90100: lmp90100@2c {
	compatible = "ti,lmp90100";
	label = "LMP90100";
	reg = <0x2c>;
	spi-max-frequency = <0>;
	drdyb-gpios = <&test_gpio 0 0>;
	#io-channel-cells = <2>;
};

test_spi_ws2812_spi: ws2812-spi@2e {
	compatible = "worldsemi,ws2812-spi";
	label = "WS2812-SPI";
	reg = <0x2e>;
	spi-max-frequency = <0>;
	spi-one-frame = <0>;
	spi-zero-frame = <0>;
	chain-length = <0>;
	/* has-white-channel; */
};

test_spi_bt_hci_spi: bt-hci-spi@2f {
	compatible = "zephyr,bt-hci-spi";
	label = "BT-HCI-SPI";
	reg = <0x2f>;
	spi-max-frequency = <0>;
	irq-gpios = <&test_gpio 0 0>;
	reset-gpios = <&test_gpio 0 0>;
};

test_spi_mmc_spi_slot: mmc-spi-slot@30 {
	compatible = "zephyr,mmc-spi-slot";
	label = "MMC-SPI-SLOT";
	reg = <0x30>;
	spi-max-frequency = <0>;
};

test_spi_iis2dh: iis2dh@31 {
	compatible = "st,iis2dh";
	label = "IIS2DH";
	reg = <0x31>;
	spi-max-frequency = <0>;
	drdy-gpios = <&test_gpio 0 0>;
};

test_spi_mcp3204: mcp3204@32 {
	compatible = "microchip,mcp3204";
	reg = <0x32>;
	spi-max-frequency = <0>;
	label = "MCP3204";
	#io-channel-cells = <1>;
};

test_spi_dac60508: dac60508@33 {
	compatible = "ti,dac60508";
	label = "DAC60508";
	reg = <0x33>;
	spi-max-frequency = <0>;
	#io-channel-cells = <1>;
	voltage-reference = <0>;
	channel0-gain = <0>;
	channel1-gain = <0>;
	channel2-gain = <0>;
	channel3-gain = <0>;
	channel4-gain = <0>;
	channel5-gain = <0>;
	channel6-gain = <0>;
	channel7-gain = <0>;
};

test_spi_dac70508: dac70508@34 {
	compatible = "ti,dac70508";
	label = "DAC70508";
	reg = <0x34>;
	spi-max-frequency = <0>;
	#io-channel-cells = <1>;
	voltage-reference = <0>;
	channel0-gain = <0>;
	channel1-gain = <0>;
	channel2-gain = <0>;
	channel3-gain = <0>;
	channel4-gain = <0>;
	channel5-gain = <0>;
	channel6-gain = <0>;
	channel7-gain = <0>;
};

test_spi_dac80508: dac80508@35 {
	compatible = "ti,dac80508";
	label = "DAC80508";
	reg = <0x35>;
	spi-max-frequency = <0>;
	#io-channel-cells = <1>;
	voltage-reference = <0>;
	channel0-gain = <0>;
	channel1-gain = <0>;
	channel2-gain = <0>;
	channel3-gain = <0>;
	channel4-gain = <0>;
	channel5-gain = <0>;
	channel6-gain = <0>;
	channel7-gain = <0>;
};

test_spi_w5500: w5500@36 {
	compatible = "wiznet,w5500";
	label = "w5500";
	reg = <0x36>;
	spi-max-frequency = <0>;
	int-gpios = <&test_gpio 0 0>;
	reset-gpios = <&test_gpio 0 0>;
};

test_spi_iis2iclx: iis2iclx@37 {
	compatible = "st,iis2iclx";
	label = "IIS2ICLX";
	reg = <0x37>;
	spi-max-frequency = <0>;
	drdy-gpios = <&test_gpio 0 0>;
	int-pin = <1>;
};

test_spi_icm42605: icm42605@38 {
	compatible = "invensense,icm42605";
	label = "ICM42605";
	reg = <0x38>;
	spi-max-frequency = <0>;
	int-gpios = <&test_gpio 0 0>;
};

test_spi_max6675: max6675@38 {
	compatible = "maxim,max6675";
	label = "MAX6675";
	reg = <0x38>;
	spi-max-frequency = <0>;
};

test_spi_bmi270: bmi270@39 {
	compatible = "bosch,bmi270";
	label = "BMI270";
	reg = <0x39>;
	spi-max-frequency = <0>;
};

test_spi_bmp388: bmp388@3a {
	compatible = "bosch,bmp388";
	label = "BMP388";
	reg = <0x3a>;
	spi-max-frequency = <0>;
	int-gpios = <&test_gpio 0 0>;
};
```

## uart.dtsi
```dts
/*
 * Copyright (c) 2020, Linaro Ltd.
 *
 * SPDX-License-Identifier: Apache-2.0
 *
 * Application overlay for uart devices
 */

test_hl7800: hl7800 {
	compatible = "swir,hl7800";
	label = "hl7800";
	mdm-reset-gpios = <&test_gpio 0 0>;
	mdm-wake-gpios = <&test_gpio 0 0>;
	mdm-pwr-on-gpios = <&test_gpio 0 0>;
	mdm-fast-shutd-gpios = <&test_gpio 0 0>;
	mdm-uart-dtr-gpios = <&test_gpio 0 0>;
	mdm-uart-dsr-gpios = <&test_gpio 0 0>;
	mdm-uart-cts-gpios = <&test_gpio 0 0>;
	mdm-gpio6-gpios = <&test_gpio 0 0>;
	mdm-vgpio-gpios = <&test_gpio 0 0>;
};

test_wnc_m14a2a: wncm14a2a {
	compatible = "wnc,m14a2a";
	label = "wnc-m14a2a";
	mdm-boot-mode-sel-gpios = <&test_gpio 0 0>;
	mdm-power-gpios = <&test_gpio 0 0>;
	mdm-keep-awake-gpios = <&test_gpio 0 0>;
	mdm-reset-gpios = <&test_gpio 0 0>;
	mdm-shld-trans-ena-gpios = <&test_gpio 0 0>;
};

test_sara_r4: sara_r4 {
      compatible = "ublox,sara-r4";
      label = "ublox-sara-r4";

      mdm-power-gpios = <&test_gpio 0 0>;
      mdm-reset-gpios = <&test_gpio 0 0>;
};

test_quectel_bg9x: quectel_bg9x {
      compatible = "quectel,bg9x";
      label = "quectel,bg9x";

      mdm-power-gpios = <&test_gpio 0 0>;
      mdm-reset-gpios = <&test_gpio 0 0>;
};

test_gsm_ppp: gsm_ppp {
	compatible = "gsm,ppp";
	label = "gsm,ppp";
};
```

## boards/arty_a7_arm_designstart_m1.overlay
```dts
/*
 * Copyright (c) 2020 Henrik Brix Andersen <henrik@brixandersen.dk>
 *
 * SPDX-License-Identifier: Apache-2.0
 */

/ {
	counter0: counter@88888888 {
		compatible = "xlnx,xps-timer-1.00.a";
		reg = <0x88888888 0x10000>;
		interrupt-parent = <&nvic>;
		interrupts = <4 0>;
		clock-frequency = <100000000>;
		xlnx,count-width = <0x20>;
		xlnx,gen0-assert = <0x1>;
		xlnx,gen1-assert = <0x1>;
		xlnx,one-timer-only = <0x0>;
		xlnx,trig0-assert = <0x1>;
		xlnx,trig1-assert = <0x1>;
		label = "COUNTER_0";
	};

	pwm0: pwm@99999999 {
		compatible = "xlnx,xps-timer-1.00.a-pwm";
		reg = <0x99999999 0x10000>;
		interrupt-parent = <&nvic>;
		interrupts = <5 0>;
		clock-frequency = <100000000>;
		xlnx,count-width = <0x20>;
		xlnx,gen0-assert = <0x1>;
		xlnx,gen1-assert = <0x1>;
		xlnx,one-timer-only = <0x0>;
		xlnx,trig0-assert = <0x1>;
		xlnx,trig1-assert = <0x0>;
		label = "PWM_0";
		#pwm-cells = <3>;
	};
};
```

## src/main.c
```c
/*
 * Copyright (c) 2012-2014 Wind River Systems, Inc.
 *
 * SPDX-License-Identifier: Apache-2.0
 */

#include <zephyr.h>
#include <sys/printk.h>


/*
 * @file
 * @brief Hello World demo
 */


void main(void)
{
	printk("Hello World!\n");
}
```
